# SF32LB57x register map
File version: 1.0
CPU: CM33 r0p1, little endian, MPU, FPU, 3 interrupt priority bits
Registers are 32-bit, read-write, reset 0x0 unless marked. A register's access mark holds for its fields unless they carry their own. Offsets are from the block's base; [hi:lo] are bit positions.

## GPTIM1
Base 0x50090000
Same registers: GPTIM2 0x500B0000
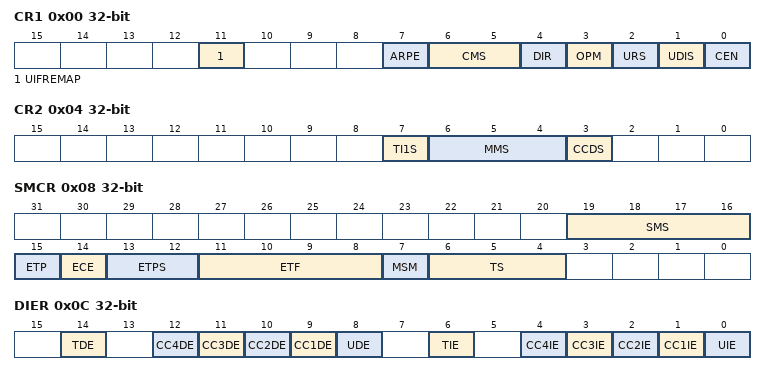
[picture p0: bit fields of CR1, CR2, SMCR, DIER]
0x00 CR1 — TIM control register 1
  [11] UIFREMAP — UIF status bit remapping 0: No remapping. UIF status bit is not copied to TIM_CNT register bit 31 1: Remapping enabled. UIF status bit is copied to TIM_CNT register bit 31.
  [7] ARPE — Auto-reload preload enable 0: TIMx_ARR register is not buffered 1: TIMx_ARR register is buffered
  [6:5] CMS — Center-aligned mode selection 00: Edge-aligned mode. The counter counts up or down depending on the direction bit (DIR). 01: Center-aligned mode 1. The counter counts up and down alternatively. Output compare interrupt flags of channels configured in output (CCxS=00 in TIMx_CCMRx register) are set only when the counter is counting down. 10: Center-aligned mode 2. The counter counts up and down alternatively. Output compare interrupt flags of channels configured in output (CCxS=00 in TIMx_CCMRx register) are set only when the counter is counting up. 11: Center-aligned mode 3. The counter counts up and down alternatively. Output compare interrupt flags of channels configured in output (CCxS=00 in TIMx_CCMRx register) are set both when the counter is counting up or down. Note: It is not allowed to switch from edge-aligned mode to center-aligned mode as long as the counter is enabled (CEN=1)
  [4] DIR — Direction 0: Counter used as upcounter 1: Counter used as downcounter Note: This bit is read only when the timer is configured in Center-aligned mode or Encoder mode
  [3] OPM — One-pulse mode 0: Counter is not stopped at update event 1: Counter stops counting at the next update event (clearing the bit CEN)
  [2] URS — Update request source This bit is set and cleared by software to select the UEV event sources. 0: Any of the following events generate an update interrupt or DMA request if enabled. These events can be: – Counter overflow/underflow – Setting the UG bit – Update generation through the slave mode controller 1: Only counter overflow/underflow generates an update interrupt or DMA request if enabled.
  [1] UDIS — Update disable This bit is set and cleared by software to enable/disable UEV event generation. 0: UEV enabled. The Update (UEV) event is generated by one of the following events: – Counter overflow/underflow – Setting the UG bit – Update generation through the slave mode controller Buffered registers are then loaded with their preload values. 1: UEV disabled. The Update event is not generated, shadow registers keep their value (ARR, PSC, CCRx). However the counter and the prescaler are reinitialized if the UG bit is set or if a hardware reset is received from the slave mode controller.
  [0] CEN — Counter enable 0: Counter disabled 1: Counter enabled Note: External clock, gated mode and encoder mode can work only if the CEN bit has been previously set by software. However trigger mode can set the CEN bit automatically by hardware. CEN is cleared automatically in one-pulse mode, when an update event occurs.
0x04 CR2 — TIM control register 2
  [7] TI1S — TI1 selection 0: The TIMx_CH1 pin is connected to TI1 input 1: The TIMx_CH1, CH2 and CH3 pins are connected to the TI1 input (XOR combination)
  [6:4] MMS — Master mode selection These bits allow to select the information to be sent in master mode to slave timers for synchronization (TRGO). The combination is as follows: 000: Reset - the UG bit from the TIMx_EGR register is used as trigger output (TRGO). If the reset is generated by the trigger input (slave mode controller configured in reset mode) then the signal on TRGO is delayed compared to the actual reset. 001: Enable - the Counter enable signal, CNT_EN, is used as trigger output (TRGO). It is useful to start several timers at the same time or to control a window in which a slave timer is enabled. The Counter Enable signal is generated by a logic OR between CEN control bit and the trigger input when configured in gated mode. When the Counter Enable signal is controlled by the trigger input, there is a delay on TRGO, except if the master/slave mode is selected (see the MSM bit description in TIMx_SMCR register). 010: Update - The update event is selected as trigger output (TRGO). For instance a master timer can then be used as a prescaler for a slave timer. 011: Compare Pulse - The trigger output send a positive pulse when the CC1IF flag is to be set (even if it was already high), as soon as a capture or a compare match occurred. (TRGO) 100: Compare - OC1REF signal is used as trigger output (TRGO) 101: Compare - OC2REF signal is used as trigger output (TRGO) 110: Compare - OC3REF signal is used as trigger output (TRGO) 111: Compare - OC4REF signal is used as trigger output (TRGO) Note: The clock of the slave timer must be enabled prior to receive events from the master timer, and must not be changed on-the-fly while triggers are received from the master timer
  [3] CCDS — Capture/compare DMA selection 0: CCx DMA request sent when CCx event occurs 1: CCx DMA requests sent when update event occurs
0x08 SMCR — TIM slave mode control register
  [19:16] SMS — Slave mode selection When external signals are selected the active edge of the trigger signal (TRGI) is linked to the polarity selected on the external input (see Input Control register and Control Register description. 0000: Slave mode disabled - if CEN = ‘1 then the prescaler is clocked directly by the internal clock. 0001: Encoder mode 1 - Counter counts up/down on TI1FP1 edge depending on TI2FP2 level. 0010: Encoder mode 2 - Counter counts up/down on TI2FP2 edge depending on TI1FP1 level. 0011: Encoder mode 3 - Counter counts up/down on both TI1FP1 and TI2FP2 edges depending on the level of the other input. 0100: Reset Mode - Rising edge of the selected trigger input (TRGI) reinitializes the counter and generates an update of the registers. 0101: Gated Mode - The counter clock is enabled when the trigger input (TRGI) is high. The counter stops (but is not reset) as soon as the trigger becomes low. Both start and stop of the counter are controlled. 0110: Trigger Mode - The counter starts at a rising edge of the trigger TRGI (but it is not reset). Only the start of the counter is controlled. 0111: External Clock Mode 1 - Rising edges of the selected trigger (TRGI) clock the counter. 1000: Combined reset + trigger mode - Rising edge of the selected trigger input (TRGI) reinitializes the counter, generates an update of the registers and starts the counter. Note: The gated mode must not be used if TI1F_ED is selected as the trigger input (TS=100). Indeed, TI1F_ED outputs 1 pulse for each transition on TI1F, whereas the gated mode checks the level of the trigger signal. Note: The clock of the slave peripherals (timer, ADC, ...) receiving the TRGO or the TRGO2 signals must be enabled prior to receive events from the master timer, and the clock frequency (prescaler) must not be changed on-the-fly while triggers are received from the master timer.
  [15] ETP — External trigger polarity This bit selects whether ETR or ETR is used for trigger operations 0: ETR is non-inverted, active at high level or rising edge 1: ETR is inverted, active at low level or falling edge
  [14] ECE — External clock enable This bit enables External clock mode 2. 0: External clock mode 2 disabled 1: External clock mode 2 enabled. The counter is clocked by any active edge on the ETRF signal. 1: Setting the ECE bit has the same effect as selecting external clock mode 1 with TRGI connected to ETRF (SMS=111 and TS=111). 2: It is possible to simultaneously use external clock mode 2 with the following slave modes: reset mode, gated mode and trigger mode. Nevertheless, TRGI must not be connected to ETRF in this case (TS bits must not be 111). 3: If external clock mode 1 and external clock mode 2 are enabled at the same time, the external clock input is ETRF.
  [13:12] ETPS — External trigger prescaler External trigger signal ETRP frequency must be at most 1/4 of CK_INT frequency. A prescaler can be enabled to reduce ETRP frequency. It is useful when inputting fast external clocks. 00: Prescaler OFF 01: ETRP frequency divided by 2 10: ETRP frequency divided by 4 11: ETRP frequency divided by 8
  [11:8] ETF — External trigger filter This bit-field then defines the frequency used to sample ETRP signal and the length of the digital filter applied to ETRP. The digital filter is made of an event counter in which N consecutive events are needed to validate a transition on the output: 0000: No filter, sampling is done at fDTS 0001: fSAMPLING=fCK_INT, N=2 0010: fSAMPLING=fCK_INT, N=4 0011: fSAMPLING=fCK_INT, N=8 0100: fSAMPLING=fDTS/2, N=6 0101: fSAMPLING=fDTS/2, N=8 0110: fSAMPLING=fDTS/4, N=6 0111: fSAMPLING=fDTS/4, N=8 1000: fSAMPLING=fDTS/8, N=6 1001: fSAMPLING=fDTS/8, N=8 1010: fSAMPLING=fDTS/16, N=5 1011: fSAMPLING=fDTS/16, N=6 1100: fSAMPLING=fDTS/16, N=8 1101: fSAMPLING=fDTS/32, N=5 1110: fSAMPLING=fDTS/32, N=6 1111: fSAMPLING=fDTS/32, N=8
  [7] MSM — Master/Slave mode 0: No action 1: The effect of an event on the trigger input (TRGI) is delayed to allow a perfect synchronization between the current timer and its slaves (through TRGO). It is useful if we want to synchronize several timers on a single external event.
  [6:4] TS — Trigger selection This bit-field selects the trigger input to be used to synchronize the counter. 000: Internal Trigger 0 (ITR0) 001: Internal Trigger 1 (ITR1) 010: Internal Trigger 2 (ITR2) 011: Internal Trigger 3 (ITR3) 100: TI1 Edge Detector (TI1F_ED) 101: Filtered Timer Input 1 (TI1FP1) 110: Filtered Timer Input 2 (TI2FP2) 111: External Trigger input (ETRF) Note: These bits must be changed only when they are not used (e.g. when SMS=000) to avoid wrong edge detections at the transition.
0x0C DIER — TIM DMA/Interrupt enable register
  [14] TDE — Trigger DMA request enable 0: Trigger DMA request disabled. 1: Trigger DMA request enabled.
  [12] CC4DE — Capture/Compare 4 DMA request enable 0: CC4 DMA request disabled. 1: CC4 DMA request enabled
  [11] CC3DE — Capture/Compare 3 DMA request enable 0: CC3 DMA request disabled. 1: CC3 DMA request enabled.
  [10] CC2DE — Capture/Compare 2 DMA request enable 0: CC2 DMA request disabled. 1: CC2 DMA request enabled.
  [9] CC1DE — Capture/Compare 1 DMA request enable 0: CC1 DMA request disabled. 1: CC1 DMA request enabled.
  [8] UDE — Update DMA request enable 0: Update DMA request disabled. 1: Update DMA request enabled
  [6] TIE — Trigger interrupt enable 0: Trigger interrupt disabled. 1: Trigger interrupt enabled
  [4] CC4IE — Capture/Compare 4 interrupt enable 0: CC4 interrupt disabled. 1: CC4 interrupt enabled
  [3] CC3IE — Capture/Compare 3 interrupt enable 0: CC3 interrupt disabled. 1: CC3 interrupt enabled
  [2] CC2IE — Capture/Compare 2 interrupt enable 0: CC2 interrupt disabled. 1: CC2 interrupt enabled.
  [1] CC1IE — Capture/Compare 1 interrupt enable 0: CC1 interrupt disabled. 1: CC1 interrupt enabled
  [0] UIE — Update interrupt enable 0: Update interrupt disabled. 1: Update interrupt enabled
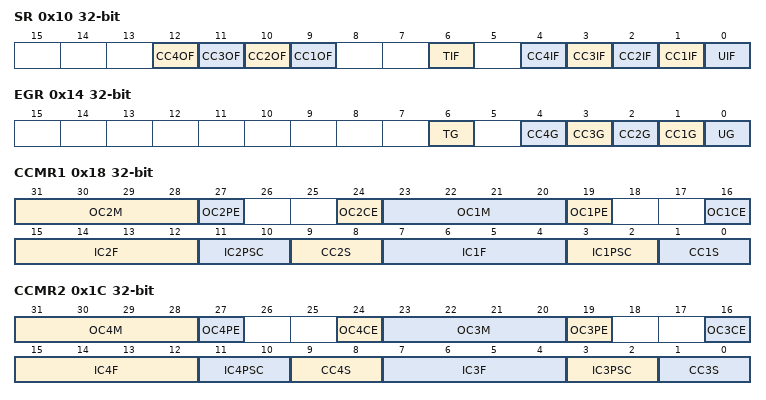
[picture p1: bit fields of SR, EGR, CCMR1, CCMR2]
0x10 SR — TIM status register
  [12] CC4OF — Capture/Compare 4 overcapture flag
  [11] CC3OF — Capture/Compare 3 overcapture flag
  [10] CC2OF — Capture/Compare 2 overcapture flag
  [9] CC1OF — Capture/Compare 1 overcapture flag This flag is set by hardware only when the corresponding channel is configured in input capture mode. It is cleared by software by writing it to ‘0’. 0: No overcapture has been detected. 1: The counter value has been captured in TIMx_CCR1 register while CC1IF flag was already set
  [6] TIF — Trigger interrupt flag This flag is set by hardware on trigger event (active edge detected on TRGI input when the slave mode controller is enabled in all modes but gated mode. It is set when the counter starts or stops when gated mode is selected. It is cleared by software. 0: No trigger event occurred. 1: Trigger interrupt pending.
  [4] CC4IF — Capture/Compare 4 interrupt flag
  [3] CC3IF — Capture/Compare 3 interrupt flag
  [2] CC2IF — Capture/Compare 2 interrupt flag
  [1] CC1IF — Capture/Compare 1 interrupt flag If channel CC1 is configured as output: This flag is set by hardware when the counter matches the compare value, with some exception in center-aligned mode (refer to the CMS bits in the TIMx_CR1 register description) and in retriggerable one pulse mode. It is cleared by software. 0: No match. 1: The content of the counter TIMx_CNT has matched the content of the TIMx_CCR1 register. If channel CC1 is configured as input: This bit is set by hardware on a capture. It is cleared by software or by reading the TIMx_CCR1 register. 0: No input capture occurred. 1: The counter value has been captured in TIMx_CCR1 register (An edge has been detected on IC1 which matches the selected polarity).
  [0] UIF — Update interrupt flag This bit is set by hardware on an update event. It is cleared by software. 0: No update occurred 1: Update interrupt pending. This bit is set by hardware when the registers are updated: At overflow or underflow (for TIM2) and if UDIS=0 in the TIMx_CR1 register. When CNT is reinitialized by software using the UG bit in TIMx_EGR register, if URS=0 and UDIS=0 in the TIMx_CR1 register. When CNT is reinitialized by a trigger event (refer to the synchro control register description), if URS=0 and UDIS=0 in the TIMx_CR1 register.
0x14 EGR — Event generation register
  [6] TG — Trigger generation This bit is set by software in order to generate an event, it is automatically cleared by hardware. 0: No action 1: The TIF flag is set in TIMx_SR register. Related interrupt or DMA transfer can occur if enabled.
  [4] CC4G — Capture/compare 4 generation
  [3] CC3G — Capture/compare 3 generation
  [2] CC2G — Capture/compare 2 generation
  [1] CC1G — Capture/compare 1 generation This bit is set by software in order to generate an event, it is automatically cleared by hardware. 0: No action 1: A capture/compare event is generated on channel 1: If channel CC1 is configured as output: CC1IF flag is set, Corresponding interrupt or DMA request is sent if enabled. If channel CC1 is configured as input: The current value of the counter is captured in TIMx_CCR1 register. The CC1IF flag is set, the corresponding interrupt or DMA request is sent if enabled. The CC1OF flag is set if the CC1IF flag was already high.
  [0] UG — Update generation This bit can be set by software, it is automatically cleared by hardware. 0: No action 1: Re-initialize the counter and generates an update of the registers. Note that the prescaler counter is cleared too (anyway the prescaler ratio is not affected). The counter is cleared if the center-aligned mode is selected or if DIR=0 (upcounting), else it takes the auto-reload value (TIMx_ARR) if DIR=1 (downcounting).
0x18 CCMR1 — TIM capture/compare mode register 1
  [31:28] OC2M — Output compare 2 mode
  [27] OC2PE — Output compare 2 preload enable
  [24] OC2CE — Output compare 2 clear enable
  [23:20] OC1M — Output compare 1 mode These bits define the behavior of the output reference signal OC1REF from which OC1 and OC1N are derived. OC1REF is active high whereas OC1 and OC1N active level depends on CC1P and CC1NP bits. 0000: Frozen - The comparison between the output compare register TIMx_CCR1 and the counter TIMx_CNT has no effect on the outputs.(this mode is used to generate a timing base). 0001: Set channel 1 to active level on match. OC1REF signal is forced high when the counter TIMx_CNT matches the capture/compare register 1 (TIMx_CCR1). 0010: Set channel 1 to inactive level on match. OC1REF signal is forced low when the counter TIMx_CNT matches the capture/compare register 1 (TIMx_CCR1). 0011: Toggle - OC1REF toggles when TIMx_CNT=TIMx_CCR1. 0100: Force inactive level - OC1REF is forced low. 0101: Force active level - OC1REF is forced high. 0110: PWM mode 1 - In upcounting, channel 1 is active as long as TIMx_CNTltTIMx_CCR1 else inactive. In downcounting, channel 1 is inactive (OC1REF=‘0) as long as TIMx_CNT>TIMx_CCR1 else active (OC1REF=1). 0111: PWM mode 2 - In upcounting, channel 1 is inactive as long as TIMx_CNTltTIMx_CCR1 else active. In downcounting, channel 1 is active as long as TIMx_CNT>TIMx_CCR1 else inactive. 1000: Retriggerable OPM mode 1 - In up-counting mode, the channel is active until a trigger event is detected (on TRGI signal). Then, a comparison is performed as in PWM mode 1 and the channels becomes inactive again at the next update. In down-counting mode, the channel is inactive until a trigger event is detected (on TRGI signal). Then, a comparison is performed as in PWM mode 1 and the channels becomes inactive again at the next update. 1001: Retriggerable OPM mode 2 - In up-counting mode, the channel is inactive until a trigger event is detected (on TRGI signal). Then, a comparison is performed as in PWM mode 2 and the channels becomes inactive again at the next update. In down-counting mode, the channel is active until a trigger event is detected (on TRGI signal). Then, a comparison is performed as in PWM mode 1 and the channels becomes active again at the next update. 1010: Reserved, 1011: Reserved, 1100: Combined PWM mode 1 - OC1REF has the same behavior as in PWM mode 1. OC1REFC is the logical OR between OC1REF and OC2REF. 1101: Combined PWM mode 2 - OC1REF has the same behavior as in PWM mode 2. OC1REFC is the logical AND between OC1REF and OC2REF. 1110: Asymmetric PWM mode 1 - OC1REF has the same behavior as in PWM mode 1. OC1REFC outputs OC1REF when the counter is counting up, OC2REF when it is counting down. 1111: Asymmetric PWM mode 2 - OC1REF has the same behavior as in PWM mode 2. OC1REFC outputs OC1REF when the counter is counting up, OC2REF when it is counting down.
  [19] OC1PE — Output compare 1 preload enable 0: Preload register on TIMx_CCR1 disabled. TIMx_CCR1 can be written at anytime, the new value is taken in account immediately. 1: Preload register on TIMx_CCR1 enabled. Read/Write operations access the preload register. TIMx_CCR1 preload value is loaded in the active register at each update event.
  [16] OC1CE — Output compare 1 clear enable 0: OC1Ref is not affected by the ETRF input 1: OC1Ref is cleared as soon as a High level is detected on ETRF input
  [15:12] IC2F — Input capture 2 filter
  [11:10] IC2PSC — Input capture 2 prescaler
  [9:8] CC2S — Capture/Compare 2 selection This bit-field defines the direction of the channel (input/output) as well as the used input. 00: CC2 channel is configured as output 01: CC2 channel is configured as input, IC2 is mapped on TI2 10: CC2 channel is configured as input, IC2 is mapped on TI1 11: CC2 channel is configured as input, IC2 is mapped on TRC. This mode is working only if an internal trigger input is selected through the TS bit (TIMx_SMCR register)
  [7:4] IC1F — Input capture 1 filter This bit-field defines the frequency used to sample TI1 input and the length of the digital filter applied to TI1. The digital filter is made of an event counter in which N consecutive events are needed to validate a transition on the output: 0000: No filter, sampling is done at fDTS 0001: fSAMPLING=fCK_INT, N=2 0010: fSAMPLING=fCK_INT, N=4 0011: fSAMPLING=fCK_INT, N=8 0100: fSAMPLING=fDTS/2, N=6 0101: fSAMPLING=fDTS/2, N=8 0110: fSAMPLING=fDTS/4, N=6 0111: fSAMPLING=fDTS/4, N=8 1000: fSAMPLING=fDTS/8, N=6 1001: fSAMPLING=fDTS/8, N=8 1010: fSAMPLING=fDTS/16, N=5 1011: fSAMPLING=fDTS/16, N=6 1100: fSAMPLING=fDTS/16, N=8 1101: fSAMPLING=fDTS/32, N=5 1110: fSAMPLING=fDTS/32, N=6 1111: fSAMPLING=fDTS/32, N=8
  [3:2] IC1PSC — Input capture 1 prescaler This bit-field defines the ratio of the prescaler acting on CC1 input (IC1). The prescaler is reset as soon as CC1E=0 (TIMx_CCER register). 00: no prescaler, capture is done each time an edge is detected on the capture input 01: capture is done once every 2 events 10: capture is done once every 4 events 11: capture is done once every 8 events
  [1:0] CC1S — Capture/Compare 1 selection This bit-field defines the direction of the channel (input/output) as well as the used input. 00: CC1 channel is configured as output 01: CC1 channel is configured as input, IC1 is mapped on TI1 10: CC1 channel is configured as input, IC1 is mapped on TI2 11: CC1 channel is configured as input, IC1 is mapped on TRC. This mode is working only if an internal trigger input is selected through TS bit (TIMx_SMCR register)
0x1C CCMR2 — TIM capture/compare mode register 2
  [31:28] OC4M — Output compare 4 mode
  [27] OC4PE — Output compare 4 preload enable
  [24] OC4CE — Output compare 4 clear enable
  [23:20] OC3M — Output compare 3 mode
  [19] OC3PE — Output compare 3 preload enable
  [16] OC3CE — Output compare 3 clear enable
  [15:12] IC4F — Input capture 4 filter
  [11:10] IC4PSC — Input capture 4 prescaler
  [9:8] CC4S — Capture/Compare 4 selection This bit-field defines the direction of the channel (input/output) as well as the used input. 00: CC4 channel is configured as output 01: CC4 channel is configured as input, IC4 is mapped on TI4 10: CC4 channel is configured as input, IC4 is mapped on TI3 11: CC4 channel is configured as input, IC4 is mapped on TRC. This mode is working only if an internal trigger input is selected through TS bit (TIMx_SMCR register)
  [7:4] IC3F — Input capture 3 filter
  [3:2] IC3PSC — Input capture 3 prescaler
  [1:0] CC3S — Capture/Compare 3 selection This bit-field defines the direction of the channel (input/output) as well as the used input. 00: CC3 channel is configured as output 01: CC3 channel is configured as input, IC3 is mapped on TI3 10: CC3 channel is configured as input, IC3 is mapped on TI4 11: CC3 channel is configured as input, IC3 is mapped on TRC. This mode is working only if an internal trigger input is selected through TS bit (TIMx_SMCR register)
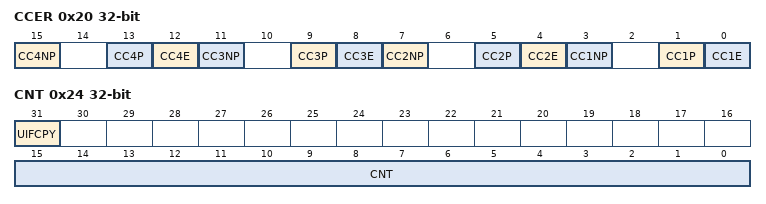
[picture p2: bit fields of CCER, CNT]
0x20 CCER — Capture/Compare enable register
  [15] CC4NP — Capture/Compare 4 output Polarity.
  [13] CC4P — Capture/Compare 4 output Polarity.
  [12] CC4E — Capture/Compare 4 output enable.
  [11] CC3NP — Capture/Compare 3 output Polarity.
  [9] CC3P — Capture/Compare 3 output Polarity.
  [8] CC3E — Capture/Compare 3 output enable.
  [7] CC2NP — Capture/Compare 2 output Polarity.
  [5] CC2P — Capture/Compare 2 output Polarity.
  [4] CC2E — Capture/Compare 2 output enable.
  [3] CC1NP — Capture/Compare 1 output Polarity. CC1 channel configured as output: CC1NP must be kept cleared in this case. CC1 channel configured as input: This bit is used in conjunction with CC1P to define TI1FP1/TI2FP1 polarity. refer to CC1P description.
  [1] CC1P — Capture/Compare 1 output Polarity. CC1 channel configured as output: 0: OC1 active high 1: OC1 active low CC1 channel configured as input: CC1NP/CC1P bits select TI1FP1 and TI2FP1 polarity for trigger or capture operations. 00: noninverted/rising edge Circuit is sensitive to TIxFP1 rising edge (capture, trigger in reset, external clock or trigger mode), TIxFP1 is not inverted (trigger in gated mode, encoder mode). 01: inverted/falling edge Circuit is sensitive to TIxFP1 falling edge (capture, trigger in reset, external clock or trigger mode), TIxFP1 is inverted (trigger in gated mode, encoder mode). 10: reserved, do not use this configuration. 11: noninverted/both edges Circuit is sensitive to both TIxFP1 rising and falling edges (capture, trigger in reset, external clock or trigger mode), TIxFP1 is not inverted (trigger in gated mode). This configuration must not be used for encoder mode.
  [0] CC1E — Capture/Compare 1 output enable. CC1 channel configured as output: 0: Off - OC1 is not active 1: On - OC1 signal is output on the corresponding output pin CC1 channel configured as input: This bit determines if a capture of the counter value can actually be done into the input capture/compare register 1 (TIMx_CCR1) or not. 0: Capture disabled 1: Capture enabled
0x24 CNT — Counter
  [31] UIFCPY — Value depends on IUFREMAP in TIMx_CR1. If UIFREMAP = 1 UIFCPY: UIF Copy This bit is a read-only copy of the UIF bit of the TIMx_ISR register
  [15:0] CNT — counter value
0x28 PSC — Prescaler
  [15:0] PSC — Prescaler value The counter clock frequency CK_CNT is equal to fCK_PSC / (PSC[15:0] + 1). PSC contains the value to be loaded in the active prescaler register at each update event (including when the counter is cleared through UG bit of TIMx_EGR register or through trigger controller when configured in “reset mode”).
0x2C ARR — Auto-reload register
  [15:0] ARR — Auto-reload value ARR is the value to be loaded in the actual auto-reload register.
0x30 RCR — Repetition counter register
  [7:0] REP — Repetition counter value These bits allow the user to set-up the update rate of the compare registers (i.e. periodic transfers from preload to active registers) when preload registers are enable, as well as the update interrupt generation rate, if this interrupt is enable. Each time the REP_CNT related downcounter reaches zero, an update event is generated and it restarts counting from REP value. As REP_CNT is reloaded with REP value only at the repetition update event U_RC, any write to the TIMx_RCR register is not taken in account until the next repetition update event. It means in PWM mode (REP+1) corresponds to the number of PWM periods in edge-aligned mode.
0x34 CCR1 — Capture/Compare register 1
  [15:0] CCR1 — Capture/Compare 1 value If channel CC1 is configured as output: CCR1 is the value to be loaded in the actual capture/compare 1 register (preload value).It is loaded permanently if the preload feature is not selected in the TIMx_CCMR1 register (bit OC1PE). Else the preload value is copied in the active capture/compare 1 register when an update event occurs. The active capture/compare register contains the value to be compared to the counter TIMx_CNT and signaled on OC1 output. If channel CC1is configured as input: CCR1 is the counter value transferred by the last input capture 1 event (IC1). The TIMx_CCR1 register is read-only and cannot be programmed.
0x38 CCR2 — Capture/Compare register 2
  [15:0] CCR2 — Capture/Compare 2 value If channel CC2 is configured as output: CCR2 is the value to be loaded in the actual capture/compare 2 register (preload value).It is loaded permanently if the preload feature is not selected in the TIMx_CCMR1 register (bit OC2PE). Else the preload value is copied in the active capture/compare 2 register when an update event occurs. The active capture/compare register contains the value to be compared to the counter TIMx_CNT and signalled on OC2 output. If channel CC2 is configured as input: CCR2 is the counter value transferred by the last input capture 2 event (IC2). The TIMx_CCR2 register is read-only and cannot be programmed.
0x3C CCR3 — Capture/Compare register 3
  [15:0] CCR3 — Capture/Compare value If channel CC3 is configured as output: CCR3 is the value to be loaded in the actual capture/compare 3 register (preload value).It is loaded permanently if the preload feature is not selected in the TIMx_CCMR2 register (bit OC3PE). Else the preload value is copied in the active capture/compare 3 register when an update event occurs. The active capture/compare register contains the value to be compared to the counter TIMx_CNT and signalled on OC3 output. If channel CC3is configured as input: CCR3 is the counter value transferred by the last input capture 3 event (IC3). The TIMx_CCR3 register is read-only and cannot be programmed.
0x40 CCR4 — Capture/Compare register 4
  [15:0] CCR4 — Capture/Compare value 1. if CC4 channel is configured as output (CC4S bits): CCR4 is the value to be loaded in the actual capture/compare 4 register (preload value).It is loaded permanently if the preload feature is not selected in the TIMx_CCMR2 register (bit OC4PE). Else the preload value is copied in the active capture/compare 4 register when an update event occurs. The active capture/compare register contains the value to be compared to the counter TIMx_CNT and signalled on OC4 output. 2. if CC4 channel is configured as input (CC4S bits in TIMx_CCMR4 register): CCR4 is the counter value transferred by the last input capture 4 event (IC4). The TIMx_CCR4 register is read-only and cannot be programmed.
0x70 DBGSEL — Debug select register
  [2:0] DBGSEL — debug select
